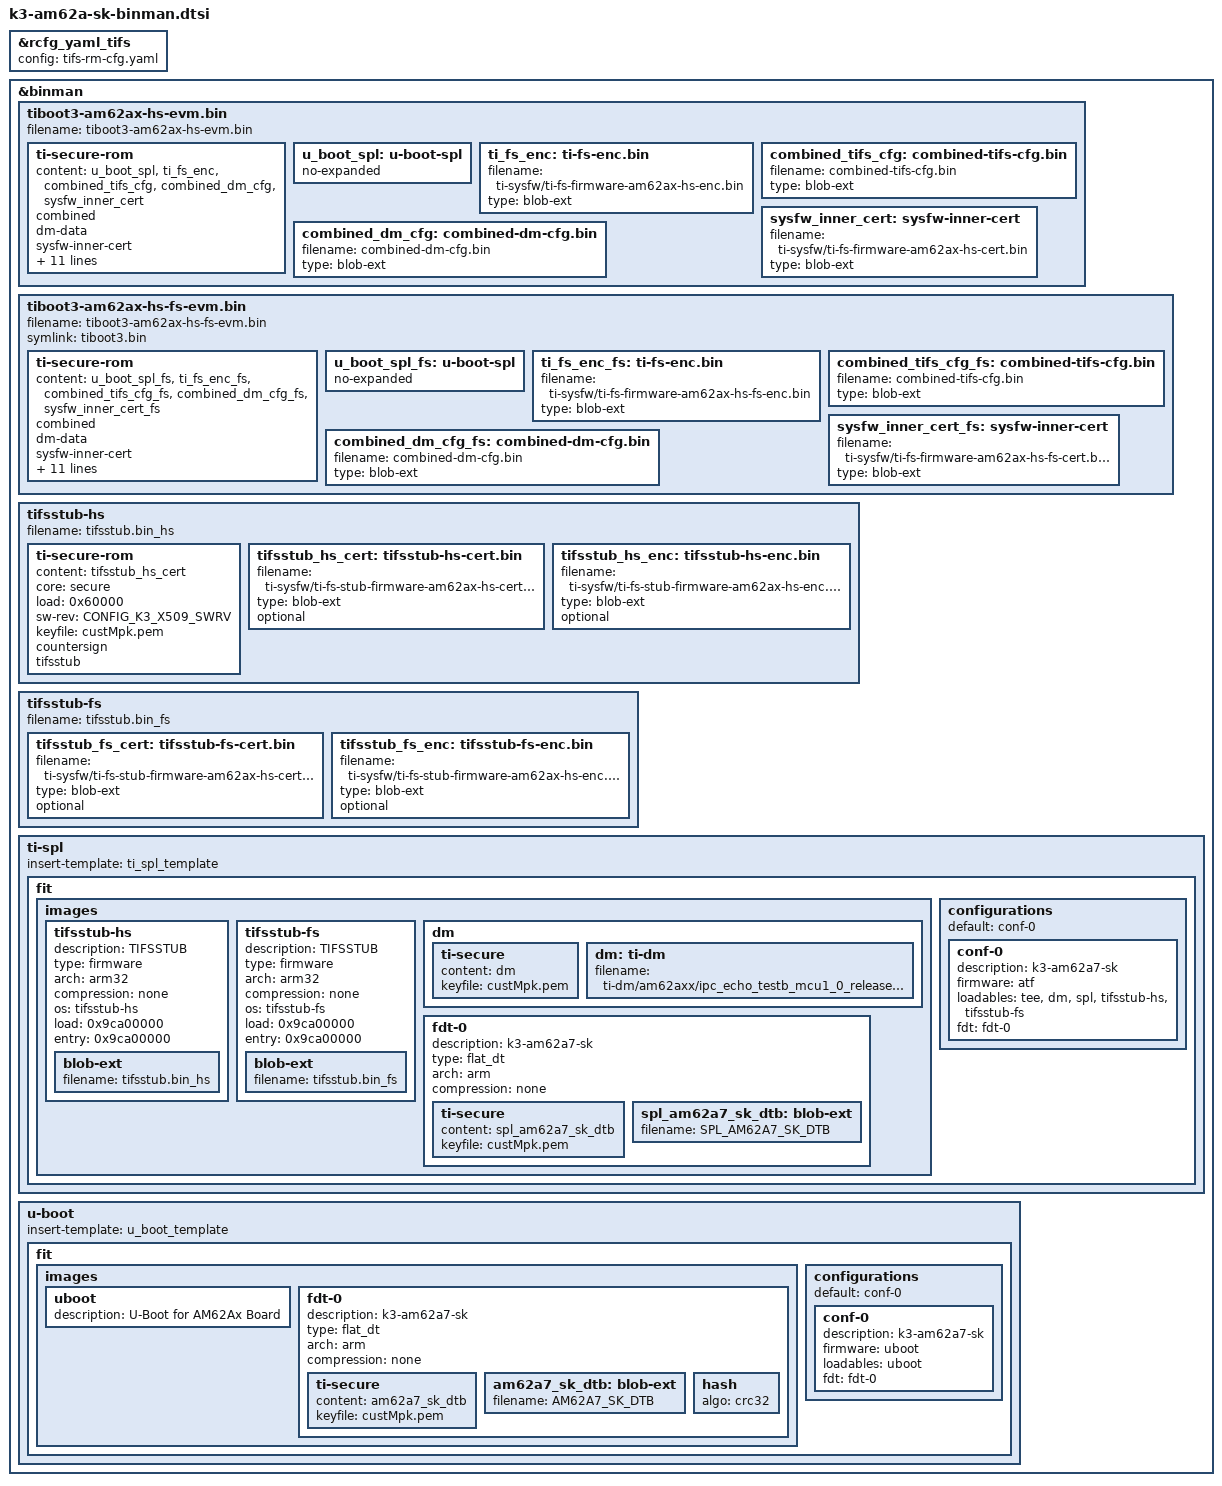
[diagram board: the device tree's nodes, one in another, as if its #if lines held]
// SPDX-License-Identifier: GPL-2.0
/*
 * Copyright (C) 2022-2023 Texas Instruments Incorporated - https://www.ti.com/
 */

#include "k3-binman.dtsi"

#ifdef CONFIG_TARGET_AM62A7_R5_EVM

&rcfg_yaml_tifs {
	config = "tifs-rm-cfg.yaml";
};

&binman {
	tiboot3-am62ax-hs-evm.bin {
		filename = "tiboot3-am62ax-hs-evm.bin";
		ti-secure-rom {
			content = <&u_boot_spl>, <&ti_fs_enc>, <&combined_tifs_cfg>,
				<&combined_dm_cfg>, <&sysfw_inner_cert>;
			combined;
			dm-data;
			sysfw-inner-cert;
			keyfile = "custMpk.pem";
			sw-rev = <1>;
			content-sbl = <&u_boot_spl>;
			content-sysfw = <&ti_fs_enc>;
			content-sysfw-data = <&combined_tifs_cfg>;
			content-sysfw-inner-cert = <&sysfw_inner_cert>;
			content-dm-data = <&combined_dm_cfg>;
			load = <CONFIG_SPL_TEXT_BASE>;
			load-sysfw = <0x40000>;
			load-sysfw-data = <0x67000>;
			load-dm-data = <0x43c3a800>;
		};
		u_boot_spl: u-boot-spl {
			no-expanded;
		};
		ti_fs_enc: ti-fs-enc.bin {
			filename = "ti-sysfw/ti-fs-firmware-am62ax-hs-enc.bin";
			type = "blob-ext";
		};
		combined_tifs_cfg: combined-tifs-cfg.bin {
			filename = "combined-tifs-cfg.bin";
			type = "blob-ext";
		};
		sysfw_inner_cert: sysfw-inner-cert {
			filename = "ti-sysfw/ti-fs-firmware-am62ax-hs-cert.bin";
			type = "blob-ext";
		};
		combined_dm_cfg: combined-dm-cfg.bin {
			filename = "combined-dm-cfg.bin";
			type = "blob-ext";
		};
	};
};

&binman {
	tiboot3-am62ax-hs-fs-evm.bin {
		filename = "tiboot3-am62ax-hs-fs-evm.bin";
		symlink = "tiboot3.bin";
		ti-secure-rom {
			content = <&u_boot_spl_fs>, <&ti_fs_enc_fs>, <&combined_tifs_cfg_fs>,
				<&combined_dm_cfg_fs>, <&sysfw_inner_cert_fs>;
			combined;
			dm-data;
			sysfw-inner-cert;
			keyfile = "custMpk.pem";
			sw-rev = <1>;
			content-sbl = <&u_boot_spl_fs>;
			content-sysfw = <&ti_fs_enc_fs>;
			content-sysfw-data = <&combined_tifs_cfg_fs>;
			content-sysfw-inner-cert = <&sysfw_inner_cert_fs>;
			content-dm-data = <&combined_dm_cfg_fs>;
			load = <CONFIG_SPL_TEXT_BASE>;
			load-sysfw = <0x40000>;
			load-sysfw-data = <0x67000>;
			load-dm-data = <0x43c3a800>;
		};
		u_boot_spl_fs: u-boot-spl {
			no-expanded;
		};
		ti_fs_enc_fs: ti-fs-enc.bin {
			filename = "ti-sysfw/ti-fs-firmware-am62ax-hs-fs-enc.bin";
			type = "blob-ext";
		};
		combined_tifs_cfg_fs: combined-tifs-cfg.bin {
			filename = "combined-tifs-cfg.bin";
			type = "blob-ext";
		};
		sysfw_inner_cert_fs: sysfw-inner-cert {
			filename = "ti-sysfw/ti-fs-firmware-am62ax-hs-fs-cert.bin";
			type = "blob-ext";
		};
		combined_dm_cfg_fs: combined-dm-cfg.bin {
			filename = "combined-dm-cfg.bin";
			type = "blob-ext";
		};
	};
};

#endif

#ifdef CONFIG_TARGET_AM62A7_A53_EVM

#define SPL_AM62A7_SK_DTB "spl/dts/ti/k3-am62a7-sk.dtb"
#define AM62A7_SK_DTB "u-boot.dtb"

&binman {
	tifsstub-hs {
		filename = "tifsstub.bin_hs";
		ti-secure-rom {
			content = <&tifsstub_hs_cert>;
			core = "secure";
			load = <0x60000>;
			sw-rev = <CONFIG_K3_X509_SWRV>;
			keyfile = "custMpk.pem";
			countersign;
			tifsstub;
		};
		tifsstub_hs_cert: tifsstub-hs-cert.bin {
			filename = "ti-sysfw/ti-fs-stub-firmware-am62ax-hs-cert.bin";
			type = "blob-ext";
			optional;
		};
		tifsstub_hs_enc: tifsstub-hs-enc.bin {
			filename = "ti-sysfw/ti-fs-stub-firmware-am62ax-hs-enc.bin";
			type = "blob-ext";
			optional;
		};
	};

	tifsstub-fs {
		filename = "tifsstub.bin_fs";
		tifsstub_fs_cert: tifsstub-fs-cert.bin {
			filename = "ti-sysfw/ti-fs-stub-firmware-am62ax-hs-cert.bin";
			type = "blob-ext";
			optional;
		};
		tifsstub_fs_enc: tifsstub-fs-enc.bin {
			filename = "ti-sysfw/ti-fs-stub-firmware-am62ax-hs-enc.bin";
			type = "blob-ext";
			optional;
		};

	};

	ti-spl {
		insert-template = <&ti_spl_template>;

		fit {
			images {
				tifsstub-hs {
					description = "TIFSSTUB";
					type = "firmware";
					arch = "arm32";
					compression = "none";
					os = "tifsstub-hs";
					load = <0x9ca00000>;
					entry = <0x9ca00000>;
					blob-ext {
						filename = "tifsstub.bin_hs";
					};
				};

				tifsstub-fs {
					description = "TIFSSTUB";
					type = "firmware";
					arch = "arm32";
					compression = "none";
					os = "tifsstub-fs";
					load = <0x9ca00000>;
					entry = <0x9ca00000>;
					blob-ext {
						filename = "tifsstub.bin_fs";
					};
				};

				dm {
					ti-secure {
						content = <&dm>;
						keyfile = "custMpk.pem";
					};
					dm: ti-dm {
						filename = "ti-dm/am62axx/ipc_echo_testb_mcu1_0_release_strip.xer5f";
					};
				};

				fdt-0 {
					description = "k3-am62a7-sk";
					type = "flat_dt";
					arch = "arm";
					compression = "none";
					ti-secure {
						content = <&spl_am62a7_sk_dtb>;
						keyfile = "custMpk.pem";
					};
					spl_am62a7_sk_dtb: blob-ext {
						filename = SPL_AM62A7_SK_DTB;
					};

				};

			};

			configurations {
				default = "conf-0";

				conf-0 {
					description = "k3-am62a7-sk";
					firmware = "atf";
					loadables = "tee", "dm", "spl",
					"tifsstub-hs", "tifsstub-fs";
					fdt = "fdt-0";
				};
			};
		};
	};
};

&binman {
	u-boot {
		insert-template = <&u_boot_template>;

		fit {
			images {
				uboot {
					description = "U-Boot for AM62Ax Board";
				};

				fdt-0 {
					description = "k3-am62a7-sk";
					type = "flat_dt";
					arch = "arm";
					compression = "none";
					ti-secure {
						content = <&am62a7_sk_dtb>;
						keyfile = "custMpk.pem";
					};
					am62a7_sk_dtb: blob-ext {
						filename = AM62A7_SK_DTB;
					};
					hash {
						algo = "crc32";
					};
				};
			};

			configurations {
				default = "conf-0";

				conf-0 {
					description = "k3-am62a7-sk";
					firmware = "uboot";
					loadables = "uboot";
					fdt = "fdt-0";
				};

			};
		};
	};
};

#endif
